# ESP32-H2 register map
Vendor: ESPRESSIF SYSTEMS (SHANGHAI) CO., LTD.; Series: ESP32 H-Series; File version: 12
CPU: RV32IMAC r0p0, little endian, no MPU, no FPU, 0 interrupt priority bits
Address unit: 32 bits
Registers are 32-bit, read-write, reset 0x0 unless marked. A register's access mark holds for its fields unless they carry their own. Offsets are from the block's base; [hi:lo] are bit positions; {n}, {i} and the like mark numbered series.

## I2C0 — I2C (Inter-Integrated Circuit) Controller 0
Base 0x60004000
Same registers: I2C1 0x60005000
0x00 SCL_LOW_PERIOD — Configures the low level width of the SCL Clock
  [8:0] SCL_LOW_PERIOD — This register is used to configure for how long SCL remains low in master mode, in I2C module clock cycles.
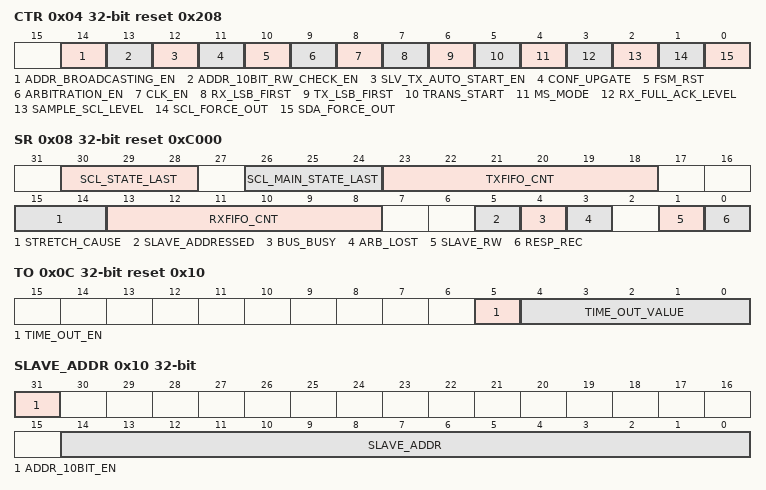
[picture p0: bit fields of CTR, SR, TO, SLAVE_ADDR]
0x04 CTR access per field reset 0x208 — Transmission setting
  [14] ADDR_BROADCASTING_EN rw — This is the enable bit to support the 7bit general call function.
  [13] ADDR_10BIT_RW_CHECK_EN rw — This is the enable bit to check if the r/w bit of 10bit addressing consists with I2C protocol
  [12] SLV_TX_AUTO_START_EN rw — This is the enable bit for slave to send data automatically
  [11] CONF_UPGATE wo — synchronization bit
  [10] FSM_RST wo — This register is used to reset the scl FMS.
  [9] ARBITRATION_EN rw — This is the enable bit for arbitration_lost.
  [8] CLK_EN rw — Reserved
  [7] RX_LSB_FIRST rw — This bit is used to control the storage mode for received data. 1: receive data from the least significant bit, 0: receive data from the most significant bit.
  [6] TX_LSB_FIRST rw — This bit is used to control the sending mode for data needing to be sent. 1: send data from the least significant bit, 0: send data from the most significant bit.
  [5] TRANS_START wo — Set this bit to start sending the data in txfifo.
  [4] MS_MODE rw — Set this bit to configure the module as an I2C Master. Clear this bit to configure the module as an I2C Slave.
  [3] RX_FULL_ACK_LEVEL rw — This register is used to configure the ACK value that need to sent by master when the rx_fifo_cnt has reached the threshold.
  [2] SAMPLE_SCL_LEVEL rw — This register is used to select the sample mode. 1: sample SDA data on the SCL low level. 0: sample SDA data on the SCL high level.
  [1] SCL_FORCE_OUT rw — 1: direct output, 0: open drain output.
  [0] SDA_FORCE_OUT rw — 1: direct output, 0: open drain output.
0x08 SR ro reset 0xC000 — Describe I2C work status.
  [30:28] SCL_STATE_LAST — This field indicates the states of the state machine used to produce SCL. 0: Idle, 1: Start, 2: Negative edge, 3: Low, 4: Positive edge, 5: High, 6: Stop
  [26:24] SCL_MAIN_STATE_LAST — This field indicates the states of the I2C module state machine. 0: Idle, 1: Address shift, 2: ACK address, 3: Rx data, 4: Tx data, 5: Send ACK, 6: Wait ACK
  [23:18] TXFIFO_CNT — This field stores the amount of received data in RAM.
  [15:14] STRETCH_CAUSE — The cause of stretching SCL low in slave mode. 0: stretching SCL low at the beginning of I2C read data state. 1: stretching SCL low when I2C Tx FIFO is empty in slave mode. 2: stretching SCL low when I2C Rx FIFO is full in slave mode.
  [13:8] RXFIFO_CNT — This field represents the amount of data needed to be sent.
  [5] SLAVE_ADDRESSED — When configured as an I2C Slave, and the address sent by the master is equal to the address of the slave, then this bit will be of high level.
  [4] BUS_BUSY — 1: the I2C bus is busy transferring data, 0: the I2C bus is in idle state.
  [3] ARB_LOST — When the I2C controller loses control of SCL line, this register changes to 1.
  [1] SLAVE_RW — When in slave mode, 1: master reads from slave, 0: master writes to slave.
  [0] RESP_REC — The received ACK value in master mode or slave mode. 0: ACK, 1: NACK.
0x0C TO reset 0x10 — Setting time out control for receiving data.
  [5] TIME_OUT_EN — This is the enable bit for time out control.
  [4:0] TIME_OUT_VALUE — This register is used to configure the timeout for receiving a data bit in APB clock cycles.
0x10 SLAVE_ADDR — Local slave address setting
  [31] ADDR_10BIT_EN — This field is used to enable the slave 10-bit addressing mode in master mode.
  [14:0] SLAVE_ADDR — When configured as an I2C Slave, this field is used to configure the slave address.
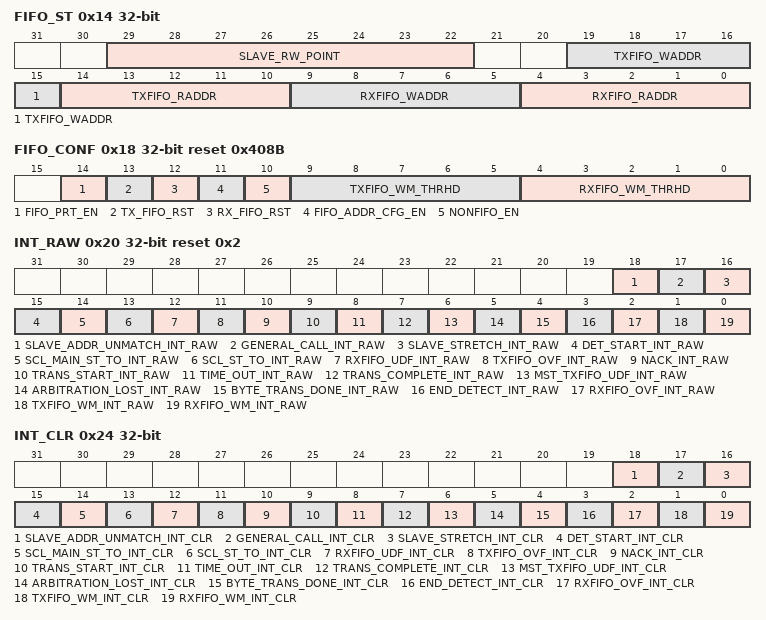
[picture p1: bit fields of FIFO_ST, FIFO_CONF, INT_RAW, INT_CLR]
0x14 FIFO_ST ro — FIFO status register.
  [29:22] SLAVE_RW_POINT — The received data in I2C slave mode.
  [19:15] TXFIFO_WADDR — This is the offset address of APB bus writing to txfifo.
  [14:10] TXFIFO_RADDR — This is the offset address of i2c module reading from txfifo.
  [9:5] RXFIFO_WADDR — This is the offset address of i2c module receiving data and writing to rxfifo.
  [4:0] RXFIFO_RADDR — This is the offset address of the APB reading from rxfifo
0x18 FIFO_CONF reset 0x408B — FIFO configuration register.
  [14] FIFO_PRT_EN — The control enable bit of FIFO pointer in non-fifo access mode. This bit controls the valid bits and the interrupts of tx/rx_fifo overflow, underflow, full and empty.
  [13] TX_FIFO_RST — Set this bit to reset tx-fifo.
  [12] RX_FIFO_RST — Set this bit to reset rx-fifo.
  [11] FIFO_ADDR_CFG_EN — When this bit is set to 1, the byte received after the I2C address byte represents the offset address in the I2C Slave RAM.
  [10] NONFIFO_EN — Set this bit to enable APB nonfifo access.
  [9:5] TXFIFO_WM_THRHD — The water mark threshold of tx FIFO in nonfifo access mode. When reg_reg_fifo_prt_en is 1 and tx FIFO counter is smaller than reg_txfifo_wm_thrhd[4:0], reg_txfifo_wm_int_raw bit will be valid.
  [4:0] RXFIFO_WM_THRHD — The water mark threshold of rx FIFO in nonfifo access mode. When reg_reg_fifo_prt_en is 1 and rx FIFO counter is bigger than reg_rxfifo_wm_thrhd[4:0], reg_rxfifo_wm_int_raw bit will be valid.
0x1C DATA ro — Rx FIFO read data.
  [7:0] FIFO_RDATA — The value of rx FIFO read data.
0x20 INT_RAW ro reset 0x2 — Raw interrupt status
  [18] SLAVE_ADDR_UNMATCH_INT_RAW — The raw interrupt bit for I2C_SLAVE_ADDR_UNMATCH_INT_RAW interrupt.
  [17] GENERAL_CALL_INT_RAW — The raw interrupt bit for I2C_GENARAL_CALL_INT interrupt.
  [16] SLAVE_STRETCH_INT_RAW — The raw interrupt bit for I2C_SLAVE_STRETCH_INT interrupt.
  [15] DET_START_INT_RAW — The raw interrupt bit for I2C_DET_START_INT interrupt.
  [14] SCL_MAIN_ST_TO_INT_RAW — The raw interrupt bit for I2C_SCL_MAIN_ST_TO_INT interrupt.
  [13] SCL_ST_TO_INT_RAW — The raw interrupt bit for I2C_SCL_ST_TO_INT interrupt.
  [12] RXFIFO_UDF_INT_RAW — The raw interrupt bit for I2C_RXFIFO_UDF_INT interrupt.
  [11] TXFIFO_OVF_INT_RAW — The raw interrupt bit for I2C_TXFIFO_OVF_INT interrupt.
  [10] NACK_INT_RAW — The raw interrupt bit for I2C_SLAVE_STRETCH_INT interrupt.
  [9] TRANS_START_INT_RAW — The raw interrupt bit for the I2C_TRANS_START_INT interrupt.
  [8] TIME_OUT_INT_RAW — The raw interrupt bit for the I2C_TIME_OUT_INT interrupt.
  [7] TRANS_COMPLETE_INT_RAW — The raw interrupt bit for the I2C_TRANS_COMPLETE_INT interrupt.
  [6] MST_TXFIFO_UDF_INT_RAW — The raw interrupt bit for I2C_TRANS_COMPLETE_INT interrupt.
  [5] ARBITRATION_LOST_INT_RAW — The raw interrupt bit for the I2C_ARBITRATION_LOST_INT interrupt.
  [4] BYTE_TRANS_DONE_INT_RAW — The raw interrupt bit for the I2C_END_DETECT_INT interrupt.
  [3] END_DETECT_INT_RAW — The raw interrupt bit for the I2C_END_DETECT_INT interrupt.
  [2] RXFIFO_OVF_INT_RAW — The raw interrupt bit for I2C_RXFIFO_OVF_INT interrupt.
  [1] TXFIFO_WM_INT_RAW — The raw interrupt bit for I2C_TXFIFO_WM_INT interrupt.
  [0] RXFIFO_WM_INT_RAW — The raw interrupt bit for I2C_RXFIFO_WM_INT interrupt.
0x24 INT_CLR wo — Interrupt clear bits
  [18] SLAVE_ADDR_UNMATCH_INT_CLR — Set this bit to clear I2C_SLAVE_ADDR_UNMATCH_INT_RAW interrupt.
  [17] GENERAL_CALL_INT_CLR — Set this bit to clear I2C_GENARAL_CALL_INT interrupt.
  [16] SLAVE_STRETCH_INT_CLR — Set this bit to clear I2C_SLAVE_STRETCH_INT interrupt.
  [15] DET_START_INT_CLR — Set this bit to clear I2C_DET_START_INT interrupt.
  [14] SCL_MAIN_ST_TO_INT_CLR — Set this bit to clear I2C_SCL_MAIN_ST_TO_INT interrupt.
  [13] SCL_ST_TO_INT_CLR — Set this bit to clear I2C_SCL_ST_TO_INT interrupt.
  [12] RXFIFO_UDF_INT_CLR — Set this bit to clear I2C_RXFIFO_UDF_INT interrupt.
  [11] TXFIFO_OVF_INT_CLR — Set this bit to clear I2C_TXFIFO_OVF_INT interrupt.
  [10] NACK_INT_CLR — Set this bit to clear I2C_SLAVE_STRETCH_INT interrupt.
  [9] TRANS_START_INT_CLR — Set this bit to clear the I2C_TRANS_START_INT interrupt.
  [8] TIME_OUT_INT_CLR — Set this bit to clear the I2C_TIME_OUT_INT interrupt.
  [7] TRANS_COMPLETE_INT_CLR — Set this bit to clear the I2C_TRANS_COMPLETE_INT interrupt.
  [6] MST_TXFIFO_UDF_INT_CLR — Set this bit to clear I2C_TRANS_COMPLETE_INT interrupt.
  [5] ARBITRATION_LOST_INT_CLR — Set this bit to clear the I2C_ARBITRATION_LOST_INT interrupt.
  [4] BYTE_TRANS_DONE_INT_CLR — Set this bit to clear the I2C_END_DETECT_INT interrupt.
  [3] END_DETECT_INT_CLR — Set this bit to clear the I2C_END_DETECT_INT interrupt.
  [2] RXFIFO_OVF_INT_CLR — Set this bit to clear I2C_RXFIFO_OVF_INT interrupt.
  [1] TXFIFO_WM_INT_CLR — Set this bit to clear I2C_TXFIFO_WM_INT interrupt.
  [0] RXFIFO_WM_INT_CLR — Set this bit to clear I2C_RXFIFO_WM_INT interrupt.
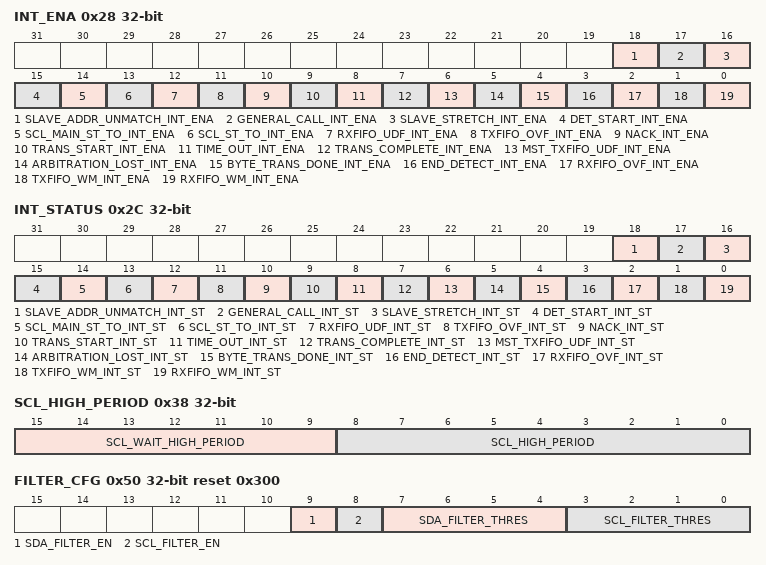
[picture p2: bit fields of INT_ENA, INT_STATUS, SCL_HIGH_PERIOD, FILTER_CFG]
0x28 INT_ENA — Interrupt enable bits
  [18] SLAVE_ADDR_UNMATCH_INT_ENA — The interrupt enable bit for I2C_SLAVE_ADDR_UNMATCH_INT interrupt.
  [17] GENERAL_CALL_INT_ENA — The interrupt enable bit for I2C_GENARAL_CALL_INT interrupt.
  [16] SLAVE_STRETCH_INT_ENA — The interrupt enable bit for I2C_SLAVE_STRETCH_INT interrupt.
  [15] DET_START_INT_ENA — The interrupt enable bit for I2C_DET_START_INT interrupt.
  [14] SCL_MAIN_ST_TO_INT_ENA — The interrupt enable bit for I2C_SCL_MAIN_ST_TO_INT interrupt.
  [13] SCL_ST_TO_INT_ENA — The interrupt enable bit for I2C_SCL_ST_TO_INT interrupt.
  [12] RXFIFO_UDF_INT_ENA — The interrupt enable bit for I2C_RXFIFO_UDF_INT interrupt.
  [11] TXFIFO_OVF_INT_ENA — The interrupt enable bit for I2C_TXFIFO_OVF_INT interrupt.
  [10] NACK_INT_ENA — The interrupt enable bit for I2C_SLAVE_STRETCH_INT interrupt.
  [9] TRANS_START_INT_ENA — The interrupt enable bit for the I2C_TRANS_START_INT interrupt.
  [8] TIME_OUT_INT_ENA — The interrupt enable bit for the I2C_TIME_OUT_INT interrupt.
  [7] TRANS_COMPLETE_INT_ENA — The interrupt enable bit for the I2C_TRANS_COMPLETE_INT interrupt.
  [6] MST_TXFIFO_UDF_INT_ENA — The interrupt enable bit for I2C_TRANS_COMPLETE_INT interrupt.
  [5] ARBITRATION_LOST_INT_ENA — The interrupt enable bit for the I2C_ARBITRATION_LOST_INT interrupt.
  [4] BYTE_TRANS_DONE_INT_ENA — The interrupt enable bit for the I2C_END_DETECT_INT interrupt.
  [3] END_DETECT_INT_ENA — The interrupt enable bit for the I2C_END_DETECT_INT interrupt.
  [2] RXFIFO_OVF_INT_ENA — The interrupt enable bit for I2C_RXFIFO_OVF_INT interrupt.
  [1] TXFIFO_WM_INT_ENA — The interrupt enable bit for I2C_TXFIFO_WM_INT interrupt.
  [0] RXFIFO_WM_INT_ENA — The interrupt enable bit for I2C_RXFIFO_WM_INT interrupt.
0x2C INT_STATUS ro — Status of captured I2C communication events
  [18] SLAVE_ADDR_UNMATCH_INT_ST — The masked interrupt status bit for I2C_SLAVE_ADDR_UNMATCH_INT interrupt.
  [17] GENERAL_CALL_INT_ST — The masked interrupt status bit for I2C_GENARAL_CALL_INT interrupt.
  [16] SLAVE_STRETCH_INT_ST — The masked interrupt status bit for I2C_SLAVE_STRETCH_INT interrupt.
  [15] DET_START_INT_ST — The masked interrupt status bit for I2C_DET_START_INT interrupt.
  [14] SCL_MAIN_ST_TO_INT_ST — The masked interrupt status bit for I2C_SCL_MAIN_ST_TO_INT interrupt.
  [13] SCL_ST_TO_INT_ST — The masked interrupt status bit for I2C_SCL_ST_TO_INT interrupt.
  [12] RXFIFO_UDF_INT_ST — The masked interrupt status bit for I2C_RXFIFO_UDF_INT interrupt.
  [11] TXFIFO_OVF_INT_ST — The masked interrupt status bit for I2C_TXFIFO_OVF_INT interrupt.
  [10] NACK_INT_ST — The masked interrupt status bit for I2C_SLAVE_STRETCH_INT interrupt.
  [9] TRANS_START_INT_ST — The masked interrupt status bit for the I2C_TRANS_START_INT interrupt.
  [8] TIME_OUT_INT_ST — The masked interrupt status bit for the I2C_TIME_OUT_INT interrupt.
  [7] TRANS_COMPLETE_INT_ST — The masked interrupt status bit for the I2C_TRANS_COMPLETE_INT interrupt.
  [6] MST_TXFIFO_UDF_INT_ST — The masked interrupt status bit for I2C_TRANS_COMPLETE_INT interrupt.
  [5] ARBITRATION_LOST_INT_ST — The masked interrupt status bit for the I2C_ARBITRATION_LOST_INT interrupt.
  [4] BYTE_TRANS_DONE_INT_ST — The masked interrupt status bit for the I2C_END_DETECT_INT interrupt.
  [3] END_DETECT_INT_ST — The masked interrupt status bit for the I2C_END_DETECT_INT interrupt.
  [2] RXFIFO_OVF_INT_ST — The masked interrupt status bit for I2C_RXFIFO_OVF_INT interrupt.
  [1] TXFIFO_WM_INT_ST — The masked interrupt status bit for I2C_TXFIFO_WM_INT interrupt.
  [0] RXFIFO_WM_INT_ST — The masked interrupt status bit for I2C_RXFIFO_WM_INT interrupt.
0x30 SDA_HOLD — Configures the hold time after a negative SCL edge.
  [8:0] TIME — This register is used to configure the time to hold the data after the negative edge of SCL, in I2C module clock cycles.
0x34 SDA_SAMPLE — Configures the sample time after a positive SCL edge.
  [8:0] TIME — This register is used to configure for how long SDA is sampled, in I2C module clock cycles.
0x38 SCL_HIGH_PERIOD — Configures the high level width of SCL
  [15:9] SCL_WAIT_HIGH_PERIOD — This register is used to configure for the SCL_FSM's waiting period for SCL high level in master mode, in I2C module clock cycles.
  [8:0] SCL_HIGH_PERIOD — This register is used to configure for how long SCL remains high in master mode, in I2C module clock cycles.
0x40 SCL_START_HOLD reset 0x8 — Configures the delay between the SDA and SCL negative edge for a start condition
  [8:0] TIME — This register is used to configure the time between the negative edge of SDA and the negative edge of SCL for a START condition, in I2C module clock cycles.
0x44 SCL_RSTART_SETUP reset 0x8 — Configures the delay between the positive edge of SCL and the negative edge of SDA
  [8:0] TIME — This register is used to configure the time between the positive edge of SCL and the negative edge of SDA for a RESTART condition, in I2C module clock cycles.
0x48 SCL_STOP_HOLD reset 0x8 — Configures the delay after the SCL clock edge for a stop condition
  [8:0] TIME — This register is used to configure the delay after the STOP condition, in I2C module clock cycles.
0x4C SCL_STOP_SETUP reset 0x8 — Configures the delay between the SDA and SCL positive edge for a stop condition
  [8:0] TIME — This register is used to configure the time between the positive edge of SCL and the positive edge of SDA, in I2C module clock cycles.
0x50 FILTER_CFG reset 0x300 — SCL and SDA filter configuration register
  [9] SDA_FILTER_EN — This is the filter enable bit for SDA.
  [8] SCL_FILTER_EN — This is the filter enable bit for SCL.
  [7:4] SDA_FILTER_THRES — When a pulse on the SDA input has smaller width than this register value in I2C module clock cycles, the I2C controller will ignore that pulse.
  [3:0] SCL_FILTER_THRES — When a pulse on the SCL input has smaller width than this register value in I2C module clock cycles, the I2C controller will ignore that pulse.
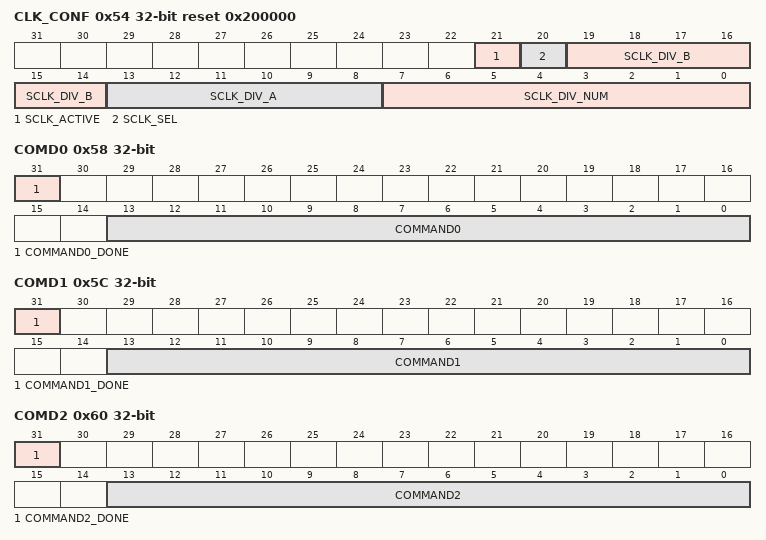
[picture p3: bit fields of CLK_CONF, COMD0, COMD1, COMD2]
0x54 CLK_CONF reset 0x200000 — I2C CLK configuration register
  [21] SCLK_ACTIVE — The clock switch for i2c module
  [20] SCLK_SEL — The clock selection for i2c module:0-XTAL,1-CLK_8MHz.
  [19:14] SCLK_DIV_B — the denominator of the fractional part of the fractional divisor for i2c module
  [13:8] SCLK_DIV_A — the numerator of the fractional part of the fractional divisor for i2c module
  [7:0] SCLK_DIV_NUM — the integral part of the fractional divisor for i2c module
0x58 COMD0 — I2C command register 0
  [31] COMMAND0_DONE — When command 0 is done in I2C Master mode, this bit changes to high level.
  [13:0] COMMAND0 — This is the content of command 0. It consists of three parts: op_code is the command, 0: RSTART, 1: WRITE, 2: READ, 3: STOP, 4: END. Byte_num represents the number of bytes that need to be sent or received. ack_check_en, ack_exp and ack are used to control the ACK bit. See I2C cmd structure for more Information.
0x5C COMD1 — I2C command register 1
  [31] COMMAND1_DONE — When command 1 is done in I2C Master mode, this bit changes to high level.
  [13:0] COMMAND1 — This is the content of command 1. It consists of three parts: op_code is the command, 0: RSTART, 1: WRITE, 2: READ, 3: STOP, 4: END. Byte_num represents the number of bytes that need to be sent or received. ack_check_en, ack_exp and ack are used to control the ACK bit. See I2C cmd structure for more Information.
0x60 COMD2 — I2C command register 2
  [31] COMMAND2_DONE — When command 2 is done in I2C Master mode, this bit changes to high Level.
  [13:0] COMMAND2 — This is the content of command 2. It consists of three parts: op_code is the command, 0: RSTART, 1: WRITE, 2: READ, 3: STOP, 4: END. Byte_num represents the number of bytes that need to be sent or received. ack_check_en, ack_exp and ack are used to control the ACK bit. See I2C cmd structure for more Information.
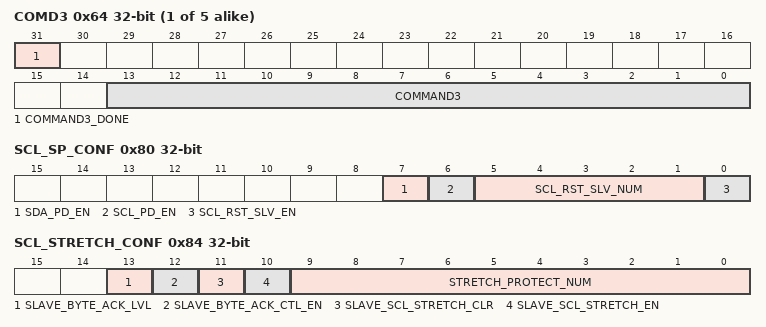
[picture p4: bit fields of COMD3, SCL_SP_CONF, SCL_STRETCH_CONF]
{0x58+4i} COMD{i} (i=3..7) — I2C command register {i}
  [31] COMMAND{i}_DONE — When command {i} is done in I2C Master mode, this bit changes to high level.
  [13:0] COMMAND{i} — This is the content of command {i}. It consists of three parts: op_code is the command, 0: RSTART, 1: WRITE, 2: READ, 3: STOP, 4: END. Byte_num represents the number of bytes that need to be sent or received. ack_check_en, ack_exp and ack are used to control the ACK bit. See I2C cmd structure for more Information.
0x78 SCL_ST_TIME_OUT reset 0x10 — SCL status time out register
  [4:0] SCL_ST_TO_I2C — The threshold value of SCL_FSM state unchanged period. It should be o more than 23
0x7C SCL_MAIN_ST_TIME_OUT reset 0x10 — SCL main status time out register
  [4:0] SCL_MAIN_ST_TO_I2C — The threshold value of SCL_MAIN_FSM state unchanged period.nIt should be o more than 23
0x80 SCL_SP_CONF — Power configuration register
  [7] SDA_PD_EN — The power down enable bit for the I2C output SDA line. 1: Power down. 0: Not power down. Set reg_sda_force_out and reg_sda_pd_en to 1 to stretch SDA low.
  [6] SCL_PD_EN — The power down enable bit for the I2C output SCL line. 1: Power down. 0: Not power down. Set reg_scl_force_out and reg_scl_pd_en to 1 to stretch SCL low.
  [5:1] SCL_RST_SLV_NUM — Configure the pulses of SCL generated in I2C master mode. Valid when reg_scl_rst_slv_en is 1.
  [0] SCL_RST_SLV_EN — When I2C master is IDLE, set this bit to send out SCL pulses. The number of pulses equals to reg_scl_rst_slv_num[4:0].
0x84 SCL_STRETCH_CONF access per field — Set SCL stretch of I2C slave
  [13] SLAVE_BYTE_ACK_LVL rw — Set the ACK level when slave controlling ACK level function enables.
  [12] SLAVE_BYTE_ACK_CTL_EN rw — The enable bit for slave to control ACK level function.
  [11] SLAVE_SCL_STRETCH_CLR wo — Set this bit to clear the I2C slave SCL stretch function.
  [10] SLAVE_SCL_STRETCH_EN rw — The enable bit for slave SCL stretch function. 1: Enable. 0: Disable. The SCL output line will be stretched low when reg_slave_scl_stretch_en is 1 and stretch event happens. The stretch cause can be seen in reg_stretch_cause.
  [9:0] STRETCH_PROTECT_NUM rw — Configure the period of I2C slave stretching SCL line.
0xF8 DATE reset 0x2201172 — Version register
  [31:0] DATE — This is the the version register.
0x100 TXFIFO_START_ADDR ro — I2C TXFIFO base address register
  [31:0] TXFIFO_START_ADDR — This is the I2C txfifo first address.
0x180 RXFIFO_START_ADDR ro — I2C RXFIFO base address register
  [31:0] RXFIFO_START_ADDR — This is the I2C rxfifo first address.
